VERSION ""

NS_ :

BS_:

BU_:

BO_ 787 ADE_A_OFFSET: 1 Vector__XXX
 SG_ CAN_ID_offset : 0|8@1+ (1,0) [0|0] "" Vector__XXX

BO_ 786 ADE_A_CANID: 2 Vector__XXX
 SG_ CAN_ID_offset : 8|8@1+ (1,0) [0|0] "" Vector__XXX
 SG_ CAN_ID_save_flag : 0|1@1+ (1,0) [0|0] "" Vector__XXX

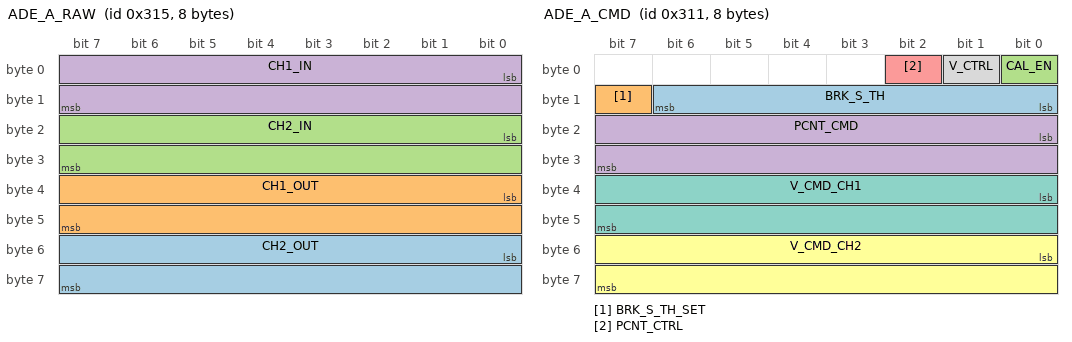
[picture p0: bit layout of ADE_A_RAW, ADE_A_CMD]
BO_ 789 ADE_A_RAW: 8 Vector__XXX
 SG_ CH2_OUT : 48|16@1+ (7.6E-005,0) [0|4.98066] "V" Vector__XXX
 SG_ CH1_OUT : 32|16@1+ (7.6E-005,0) [0|4.98066] "V" Vector__XXX
 SG_ CH2_IN : 16|16@1+ (7.6E-005,0) [0|4.98066] "V" Vector__XXX
 SG_ CH1_IN : 0|16@1+ (7.6E-005,0) [0|4.98066] "V" Vector__XXX

BO_ 785 ADE_A_CMD: 8 Vector__XXX
 SG_ BRK_S_TH : 8|7@1+ (1,0) [0|99] "%" Vector__XXX
 SG_ BRK_S_TH_SET : 15|1@1+ (1,0) [0|1] "" Vector__XXX
 SG_ CAL_EN : 0|1@1+ (1,0) [0|1] "" Vector__XXX
 SG_ PCNT_CMD : 16|16@1+ (0.001526,0) [0|100.006] "%" Vector__XXX
 SG_ PCNT_CTRL : 2|1@1+ (1,0) [0|1] "" Vector__XXX
 SG_ V_CMD_CH2 : 48|16@1+ (7.6E-005,0) [0|4.98066] "V" Vector__XXX
 SG_ V_CMD_CH1 : 32|16@1+ (7.6E-005,0) [0|4.98066] "V" Vector__XXX
 SG_ V_CTRL : 1|1@1+ (1,0) [0|1] "" Vector__XXX

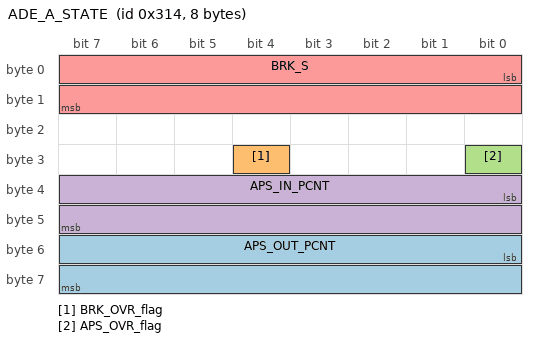
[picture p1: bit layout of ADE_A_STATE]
BO_ 788 ADE_A_STATE: 8 Vector__XXX
 SG_ APS_OUT_PCNT : 48|16@1+ (0.001526,0) [0|100.006] "%" Vector__XXX
 SG_ BRK_OVR_flag : 28|1@1+ (1,0) [0|1] "" Vector__XXX
 SG_ APS_OVR_flag : 24|1@1+ (1,0) [0|1] "" Vector__XXX
 SG_ APS_IN_PCNT : 32|16@1+ (0.001526,0) [0|100.006] "%" Vector__XXX
 SG_ BRK_S : 0|16@1+ (0.001526,0) [0|100.006] "" Vector__XXX
